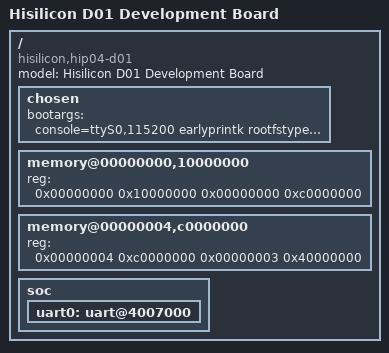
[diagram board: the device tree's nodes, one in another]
/*
 *  Copyright (C) 2013-2014 Linaro Ltd.
 *  Author: Haojian Zhuang <haojian.zhuang@linaro.org>
 *
 *  This program is free software; you can redistribute it and/or modify
 *  it under the terms of the GNU General Public License version 2 as
 *  publishhed by the Free Software Foundation.
 */

/dts-v1/;

#include "hip04.dtsi"

/ {
	/* memory bus is 64-bit */
	#address-cells = <2>;
	#size-cells = <2>;
	model = "Hisilicon D01 Development Board";
	compatible = "hisilicon,hip04-d01";

	chosen {
/*		bootargs = "console=ttyS0,115200 earlyprintk root=/dev/sda2 rw"; */
		bootargs = "console=ttyS0,115200 earlyprintk rootfstype=nfsroot root=/dev/nfs rw nfsroot=192.168.1.102:/binary ip=192.168.1.12:192.168.1.102:192.168.1.102:255.255.255.0::eth0:on:192.168.1.102:8.8.8.8 user_debug=31";
	};

	memory@00000000,10000000 {
		device_type = "memory";
		reg = <0x00000000 0x10000000 0x00000000 0xc0000000>;
	};

	memory@00000004,c0000000 {
		device_type = "memory";
		reg = <0x00000004 0xc0000000 0x00000003 0x40000000>;
	};

	soc {
		uart0: uart@4007000 {
			status = "ok";
		};
	};
};
